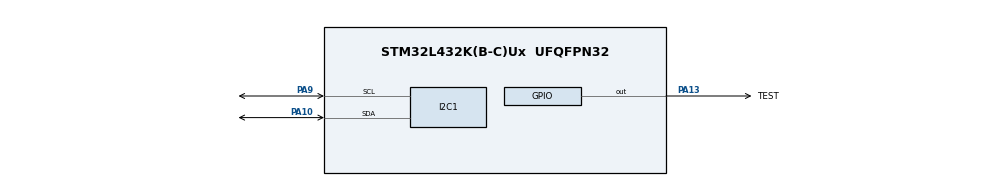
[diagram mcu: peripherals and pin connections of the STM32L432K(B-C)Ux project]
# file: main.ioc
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Mcu.Family=STM32L4
Mcu.Name=STM32L432K(B-C)Ux
Mcu.Package=UFQFPN32
NVIC.PriorityGroup=NVIC_PRIORITYGROUP_4
PA10.Mode=I2C
PA10.Signal=I2C1_SDA
PA13\ (JTMS-SWDIO).GPIO_Label=TEST
PA13\ (JTMS-SWDIO).Signal=GPIO_Output
PA9.Mode=I2C
PA9.Signal=I2C1_SCL
ProjectManager.HeapSize=0x200
ProjectManager.StackSize=0x400
ProjectManager.TargetToolchain=STM32CubeIDE
RCC.HSE_VALUE=8000000
RCC.HSI48_VALUE=48000000
RCC.HSI_VALUE=16000000
RCC.LSE_VALUE=32768
RCC.MSI_VALUE=4000000
RCC.VCOOutputFreq_Value=32000000
board=custom

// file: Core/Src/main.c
/* USER CODE BEGIN Header */
/**
  ******************************************************************************
  * @file           : main.c
  * @brief          : Main program body
  ******************************************************************************
  * @attention
  *
  * Copyright (c) 2023 STMicroelectronics.
  * All rights reserved.
  *
  * This software is licensed under terms that can be found in the LICENSE file
  * in the root directory of this software component.
  * If no LICENSE file comes with this software, it is provided AS-IS.
  *
  ******************************************************************************
  */
/* USER CODE END Header */
#include "main.h"
#include "i2c.h"
#include "gpio.h"

/* USER CODE BEGIN Includes */
#include "pca9685.h"
#include "stdint.h"
#include "steps.h"
/* USER CODE END Includes */

void SystemClock_Config(void);

int main(void)
{

  /* MCU Configuration--------------------------------------------------------*/

  /* Reset of all peripherals, Initializes the Flash interface and the Systick. */
  HAL_Init();

  /* Configure the system clock */
  SystemClock_Config();

  /* Initialize all configured peripherals */
  MX_GPIO_Init();
  MX_I2C1_Init();
  /* USER CODE BEGIN 2 */

  PCA9685_Init(&hi2c1);
    PCA9685_SetServoAngle(0, 0);
    PCA9685_SetServoAngle(1, 0);
    PCA9685_SetServoAngle(2, 0);
    PCA9685_SetServoAngle(3, 0);
    PCA9685_SetServoAngle(4, 0);
    PCA9685_SetServoAngle(5, 0);
    PCA9685_SetServoAngle(6, 0);
    PCA9685_SetServoAngle(8, 0);
    PCA9685_SetServoAngle(9, 0);
    PCA9685_SetServoAngle(10, 0);
    PCA9685_SetServoAngle(11, 0);
    PCA9685_SetServoAngle(12, 0);
    HAL_Delay(1000);
  /* USER CODE END 2 */
    HAL_Delay(1500);
    Set();
    HAL_Delay(1500);
    first();
     HAL_Delay(1500);
  /* Infinite loop */
  /* USER CODE BEGIN WHILE */

  while (1)
  {

	    	second();
	    	HAL_Delay(100);
	     third();
	      HAL_Delay(100);
	      forth();
	      HAL_Delay(100);
	      five();
	      HAL_Delay(100);
	      second();
	      	    	HAL_Delay(100);
	      	     third();
	      	      HAL_Delay(100);
	      	      forth();
	      	      HAL_Delay(100);
	      	      five();
	      	      HAL_Delay(100);
	      	    second();
	      	    	    	HAL_Delay(100);
	      	    	     third();
	      	    	      HAL_Delay(100);
	      	    	      forth();
	      	    	      HAL_Delay(100);
	      	    	      five();
	      	    	      HAL_Delay(100);
    /* USER CODE END WHILE */

  }
}

void SystemClock_Config(void)
{
  RCC_OscInitTypeDef RCC_OscInitStruct = {0};
  RCC_ClkInitTypeDef RCC_ClkInitStruct = {0};

  /** Configure the main internal regulator output voltage
  */
  if (HAL_PWREx_ControlVoltageScaling(PWR_REGULATOR_VOLTAGE_SCALE1) != HAL_OK)
  {
    Error_Handler();
  }
  /** Initializes the RCC Oscillators according to the specified parameters
  * in the RCC_OscInitTypeDef structure.
  */
  RCC_OscInitStruct.OscillatorType = RCC_OSCILLATORTYPE_MSI;
  RCC_OscInitStruct.MSIState = RCC_MSI_ON;
  RCC_OscInitStruct.MSICalibrationValue = 0;
  RCC_OscInitStruct.MSIClockRange = RCC_MSIRANGE_6;
  RCC_OscInitStruct.PLL.PLLState = RCC_PLL_NONE;
  if (HAL_RCC_OscConfig(&RCC_OscInitStruct) != HAL_OK)
  {
    Error_Handler();
  }
  /** Initializes the CPU, AHB and APB buses clocks
  */
  RCC_ClkInitStruct.ClockType = RCC_CLOCKTYPE_HCLK|RCC_CLOCKTYPE_SYSCLK
                              |RCC_CLOCKTYPE_PCLK1|RCC_CLOCKTYPE_PCLK2;
  RCC_ClkInitStruct.SYSCLKSource = RCC_SYSCLKSOURCE_MSI;
  RCC_ClkInitStruct.AHBCLKDivider = RCC_SYSCLK_DIV1;
  RCC_ClkInitStruct.APB1CLKDivider = RCC_HCLK_DIV1;
  RCC_ClkInitStruct.APB2CLKDivider = RCC_HCLK_DIV1;

  if (HAL_RCC_ClockConfig(&RCC_ClkInitStruct, FLASH_LATENCY_0) != HAL_OK)
  {
    Error_Handler();
  }
}

void Error_Handler(void)
{
  __disable_irq();
  while (1)
  {
  }
}
